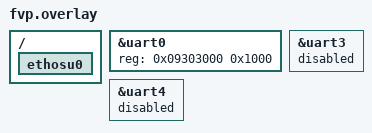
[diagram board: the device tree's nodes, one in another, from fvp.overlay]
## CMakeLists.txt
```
# SPDX-License-Identifier: Apache-2.0

cmake_minimum_required(VERSION 3.20.0)

# The AI layer adds its Kconfig fragments before Zephyr processes configuration.
add_subdirectory(ai_layer)

# Include the NPU node even when an older build cache has an empty overlay list.
if(NOT DTC_OVERLAY_FILE)
  set(DTC_OVERLAY_FILE "${CMAKE_CURRENT_SOURCE_DIR}/app.overlay")
endif()

find_package(Zephyr REQUIRED HINTS $ENV{ZEPHYR_BASE})
project(my_app)

# Zephyr already provides sys/types.h for AC6; the bare-metal pack shim
# must not shadow it. Only libc++ needs compatibility adjustments here.
if(CMAKE_CXX_COMPILER_ID STREQUAL "ARMClang")
  # AC6 6.24's register coalescer crashes on this pack's quantization code
  # with hard-float at both -Og and -O1. Keep the workaround on that file.
  if(CMAKE_CXX_COMPILER_VERSION VERSION_EQUAL "6.24.0" AND CONFIG_FP_HARDABI)
    get_target_property(_et_sources cmsis_executorch SOURCES)
    foreach(_source IN LISTS _et_sources)
      if(_source MATCHES "[/\\\\]op_quantize\\.cpp$")
        set_property(SOURCE "${_source}" TARGET_DIRECTORY cmsis_executorch
          APPEND PROPERTY COMPILE_OPTIONS -O0)
      endif()
    endforeach()
  endif()

  # Zephyr explicitly adds AC6's C resource headers as system includes.
  # AC6 6.24's libc++ wrappers must precede them (notably stddef.h).
  get_filename_component(_ac6_bin "${CMAKE_CXX_COMPILER}" DIRECTORY)
  get_filename_component(_ac6_libcxx "${_ac6_bin}/../include/libcxx" ABSOLUTE)
  if(IS_DIRECTORY "${_ac6_libcxx}")
    target_include_directories(zephyr_interface SYSTEM BEFORE INTERFACE
      "$<$<COMPILE_LANGUAGE:CXX>:${_ac6_libcxx}>")
  endif()
  zephyr_compile_options(
    "$<$<COMPILE_LANGUAGE:CXX>:-include${CMAKE_CURRENT_SOURCE_DIR}/src/zephyr_ac6_compat.hpp>")

  # Zephyr's CMake scatter generator disables CONFIG_STATIC_INIT_GNU,
  # omitting the constructor runner and the companion destructor handler.
  if(NOT CONFIG_STATIC_INIT_GNU)
    zephyr_linker_section_configure(SECTION ctors
      INPUT ".init_array*" SORT NAME KEEP
      SYMBOLS __ac6_init_array_start __ac6_init_array_end)
    zephyr_link_libraries("--keep=*.o(.init_array*)")
    target_sources(app PRIVATE src/zephyr_ac6_init.c
      "${ZEPHYR_BASE}/lib/cpp/abi/cpp_dtors.c")
  endif()

  # Zephyr hard-codes microlib for armlink. ExecuTorch's full libc++ needs
  # the standard Arm C runtime (wide strings and AEABI assertions).
  foreach(_elf zephyr_pre0 zephyr_pre1 zephyr_final)
    if(TARGET ${_elf})
      get_target_property(_libs ${_elf} LINK_LIBRARIES)
      list(REMOVE_ITEM _libs "--library_type=microlib")
      set_property(TARGET ${_elf} PROPERTY LINK_LIBRARIES "${_libs}")
    endif()
  endforeach()
endif()

target_sources(app PRIVATE
  src/main.c
  src/arm_embedded_module.cpp
  src/executorch_test.cpp
)

# Keep runtime logging consistent with the existing AI layer configuration.
zephyr_compile_definitions(ET_LOG_ENABLED=0)
```

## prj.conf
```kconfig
# M55_HP boot address used by the board's existing Alif boot configuration.
CONFIG_USE_DT_CODE_PARTITION=n
CONFIG_FLASH_LOAD_OFFSET=0x200000

# E8 NPU-HG: Ethos-U85 with 256 MACs per cycle.
CONFIG_ETHOS_U=y
CONFIG_ETHOS_U85_256=y
CONFIG_ETHOS_U_ARM=y
#CONFIG_ETHOS_U_LOG_LEVEL_NONE=y

# Ethos-U synchronization uses the kernel heap.
CONFIG_HEAP_MEM_POOL_SIZE=16384
# C++ allocations must use a heap initialized by Zephyr, including with AC6.
CONFIG_COMMON_LIBC_MALLOC=y
CONFIG_COMMON_LIBC_MALLOC_ARENA_SIZE=65536
CONFIG_LOG=y
# Keep the boot banner and kernel logs in order with the runtime's direct printf.
CONFIG_LOG_MODE_IMMEDIATE=y
CONFIG_ETHOS_U_LOG_LEVEL_INF=y
CONFIG_CACHE_MANAGEMENT=y
CONFIG_ETHOS_U_DCACHE=y

CONFIG_CPP=y
CONFIG_STD_CPP17=y

# Use the Cortex-M hardware FPU and pass floating-point arguments in FP registers.
CONFIG_FPU=y
CONFIG_FP_HARDABI=y

# Runtime loading uses C++ containers; the runner also prints float logits.
CONFIG_MAIN_STACK_SIZE=16384
CONFIG_REQUIRES_FLOAT_PRINTF=y
```

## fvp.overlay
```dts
/* SPDX-License-Identifier: Apache-2.0 */

/*
 * The Corstone-320 Zephyr board already declares its Ethos-U85. Keep this
 * overlay separate from app.overlay, which contains the Alif E8 NPU node.
 */

/* The installed SSE-320 FVP uses the BSP's FPGA UART window at 0x59303000.
 * reg is relative to the peripheral bus's 0x50000000 base.
 */
&uart0 {
	reg = <0x09303000 0x1000>;
};

/* These external UARTs use GPIO pin muxing that faults on the FVP.
 * Keep the UART0 console; the application does not use UART3 or UART4.
 */
&uart3 {
	status = "disabled";
};

&uart4 {
	status = "disabled";
};

/ {
	ethosu0 {
		status = "okay";
	};
};
```

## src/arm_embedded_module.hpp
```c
/*
 * Copyright (c) Meta Platforms, Inc. and affiliates.
 * All rights reserved.
 *
 * This source code is licensed under the BSD-style license found in
 * src/LICENSE-ExecuTorch (the ExecuTorch license).
 *
 * Customization for embedded systems by Arm.
 */
#pragma once

#include <executorch/runtime/executor/program.h>
#include <executorch/runtime/core/data_loader.h>

#include <memory>
#include <string>
#include <unordered_map>
#include <unordered_set>
#include <vector>

using namespace ::executorch::runtime;

namespace arm
{
  namespace embedded
  {

    /**
     * A facade class for loading programs and executing methods within them.
     */
    class EmbeddedModule
    {
    public:
      /**
       * Constructs an instance with the provided PTE data and memory allocators.
       *
       * @param[in] pte_data Pointer to the ExecuTorch program data to load.
       * @param[in] pte_size Size of the ExecuTorch program data to load.
       * @param[in] memory_allocator A MemoryAllocator used for memory planning.
       * @param[in] temp_allocator A MemoryAllocator to use when allocating
       * temporary data during kernel or delegate execution.
       */
      explicit EmbeddedModule(
          const unsigned char *pte_data,
          size_t pte_size,
          std::unique_ptr<DataLoader> data_loader = nullptr,
          std::unique_ptr<MemoryAllocator> memory_allocator = nullptr,
          std::unique_ptr<MemoryAllocator> temp_allocator = nullptr);

      /**
       * Loads the program if needed.
       *
       * @param[in] verification The type of verification to do before returning
       * success.
       *
       * @returns An Error to indicate success or failure of the loading process.
       */
      ET_NODISCARD Error load(
          const Program::Verification verification =
              Program::Verification::Minimal);

      /**
       * Checks if the program is loaded.
       *
       * @returns true if the program is loaded, false otherwise.
       */
      inline bool is_loaded() const
      {
        return program_ != nullptr;
      }

      /**
       * Get the program. The data loader used by the program is guaranteed to be
       * valid for the lifetime of the program.
       *
       * @returns Shared pointer to the program or nullptr if it's not yet loaded.
       */
      inline std::shared_ptr<Program> program() const
      {
        return program_;
      }

      /**
       * Get the number of methods available in the loaded program.
       *
       * @returns A Result object containing either the number of methods available
       *          or an error to indicate failure.
       */
      Result<size_t> num_methods();

      /**
       * Get a list of method names available in the loaded program.
       * Loads the program and method if needed.
       *
       * @returns A set of strings containing the names of the methods, or an error
       * if the program or method failed to load.
       */
      Result<std::unordered_set<std::string>> method_names();

      /**
       * Load a specific method from the program and set up memory management if
       * needed. The loaded method is cached to reuse the next time it's executed.
       *
       * @param[in] method_name The name of the method to load.
       * @param[in] planned_memory The memory-planned buffers to use for mutable
       * tensor data when executing a method.
       * @param[in] event_tracer Per-method event tracer to profile/trace methods
       * individually. When not given, the event tracer passed to the
       * EmbeddedModule constructor is used. Otherwise, this per-method event tracer
       * takes precedence.
       *
       * @returns An Error to indicate success or failure.
       */
      ET_NODISCARD
      Error load_method(
          const std::string &method_name,
          HierarchicalAllocator *planned_memory = nullptr,
          EventTracer *event_tracer = nullptr);

      #if 0
      ET_DEPRECATED ET_NODISCARD Error inline load_method(
          const std::string &method_name,
          EventTracer *event_tracer)
      {
        return load_method(method_name, nullptr, event_tracer);
      }
      #endif

      /**
       * Unload a specific method from the program.
       *
       * @param[in] method_name The name of the method to unload.
       *
       * @returns True if the method is unloaded, false if no-op.
       */
      inline bool unload_method(const std::string &method_name)
      {
        return methods_.erase(method_name);
      }

      #if 0
      /**
       * DEPRECATED: EmbeddedModule manages each Method exclusively.
       *
       * Get a method by it's name. Not recommended to use this method directly as
       * an end user. It's exposed to allow for composability of module in apis that
       * operate on method.
       *
       * @param[in] method_name The name of the method to get.
       *
       * @returns A Result object containing either a pointer to the requested
       *          method or an error to indicate failure.
       */
      ET_DEPRECATED ET_NODISCARD Result<Method *> method(
          const std::string &method_name);
      #endif

      /**
       * Checks if a specific method is loaded.
       *
       * @param[in] method_name The name of the method to check.
       *
       * @returns true if the method specified by method_name is loaded, false
       * otherwise.
       */
      inline bool is_method_loaded(const std::string &method_name) const
      {
        return methods_.count(method_name);
      }

      /**
       * Get a method metadata struct by method name.
       * Loads the program if needed.
       *
       * @param[in] method_name The name of the method to get the metadata for.
       *
       * @returns A method metadata, or an error if the program or method failed to
       * load.
       */
      Result<MethodMeta> method_meta(const std::string &method_name);

      /**
       * Execute a specific method with the given input values and retrieve the
       * output values. Loads the program and method before executing if needed.
       *
       * @param[in] method_name The name of the method to execute.
       * @param[in] input_values A vector of input values to be passed to the
       * method.
       *
       * @returns A Result object containing either a vector of output values
       *          from the method or an error to indicate failure.
       */
      ET_NODISCARD Result<std::vector<EValue>> execute(
          const std::string &method_name,
          const std::vector<EValue> &input_values);

      /**
       * Execute a specific method with a single input value.
       * Loads the program and method before executing if needed.
       *
       * @param[in] method_name The name of the method to execute.
       * @param[in] input_value A value to be passed to the method.
       *
       * @returns A Result object containing either a vector of output values
       *          from the method or an error to indicate failure.
       */
      ET_NODISCARD inline Result<std::vector<EValue>> execute(
          const std::string &method_name,
          const EValue &input_value)
      {
        return execute(method_name, std::vector<EValue>{input_value});
      }

      /**
       * Execute a specific method without any input values.
       * Loads the program and method before executing if needed.
       *
       * @param[in] method_name The name of the method to execute.
       *
       * @returns A Result object containing either a vector of output values
       *          from the method or an error to indicate failure.
       */
      ET_NODISCARD inline Result<std::vector<EValue>> execute(
          const std::string &method_name)
      {
        return execute(method_name, std::vector<EValue>{});
      }

      /**
       * Retrieve the output value of a specific method with the given input values.
       * Loads the program and method before execution if needed.
       *
       * @param[in] method_name The name of the method to execute.
       * @param[in] input_values A vector of input values to be passed to the
       * method.
       *
       * @returns A Result object containing either the first output value from the
       * method or an error to indicate failure.
       */
      ET_NODISCARD inline Result<EValue> get(
          const std::string &method_name,
          const std::vector<EValue> &input_values)
      {
        auto execute_result = execute(method_name, input_values);
        if (!execute_result.ok())
        {
          return execute_result.error();
        }
        auto result = std::move(*execute_result);
        if (result.empty())
        {
          return Error::InvalidArgument;
        }
        return result[0];
      }

      /**
       * Retrieve the output value of a specific method with a single input value.
       * Loads the program and method before execution if needed.
       *
       * @param[in] method_name The name of the method to execute.
       * @param[in] input_value A value to be passed to the method.
       *
       * @returns A Result object containing either the first output value from the
       * method or an error to indicate failure.
       */
      ET_NODISCARD inline Result<EValue> get(
          const std::string &method_name,
          const EValue &input_value)
      {
        return get(method_name, std::vector<EValue>{input_value});
      }

      /**
       * Retrieve the output value of a specific method without any input values.
       * Loads the program and method before execution if needed.
       *
       * @param[in] method_name The name of the method to execute.
       *
       * @returns A Result object containing either the first output value from the
       * method or an error to indicate failure.
       */
      ET_NODISCARD inline Result<EValue> get(
          const std::string &method_name)
      {
        return get(method_name, std::vector<EValue>{});
      }

      /**
       * Execute the 'forward' method with the given input values and retrieve the
       * output values. Loads the program and method before executing if needed.
       *
       * @param[in] input_values A vector of input values for the 'forward' method.
       *
       * @returns A Result object containing either a vector of output values
       *          from the 'forward' method or an error to indicate failure.
       */
      ET_NODISCARD inline Result<std::vector<EValue>> forward(
          const std::vector<EValue> &input_values)
      {
        return execute("forward", input_values);
      };

      /**
       * Execute the 'forward' method with a single value.
       * Loads the program and method before executing if needed.
       *
       * @param[in] input_value A value for the 'forward' method.
       *
       * @returns A Result object containing either a vector of output values
       *          from the 'forward' method or an error to indicate failure.
       */
      ET_NODISCARD inline Result<std::vector<EValue>> forward(
          const EValue &input_value)
      {
        return forward(std::vector<EValue>{input_value});
      }

      /**
       * Execute the 'forward' method without any input values.
       * Loads the program and method before executing if needed.
       *
       * @returns A Result object containing either a vector of output values
       *          from the method or an error to indicate failure.
       */
      ET_NODISCARD inline Result<std::vector<EValue>> forward()
      {
        return forward(std::vector<EValue>{});
      }

      /**
       * Sets a single input value for a specific method.
       *
       * @param[in] method_name The name of the method.
       * @param[in] input_value The EValue to set as the method input.
       * @param[in] input_index Zero-based index of the input to set.
       *
       * @returns An Error to indicate success or failure.
       */
      ET_NODISCARD
      Error set_input(
          const std::string &method_name,
          const EValue &input_value,
          size_t input_index);

      /**
       * Sets a single input value for the "forward" method.
       *
       * @param[in] input_value The EValue to set as the method input.
       * @param[in] input_index Zero-based index of the input to set.
       *
       * @returns An Error to indicate success or failure.
       */
      ET_NODISCARD
      inline Error set_input(
          const EValue &input_value,
          size_t input_index)
      {
        return set_input("forward", input_value, input_index);
      }

      /**
       * Sets all input values for a specific method.
       *
       * @param[in] method_name The name of the method.
       * @param[in] input_values A vector of EValues to set as the method inputs.
       *
       * @returns An Error to indicate success or failure.
       */
      ET_NODISCARD
      Error set_inputs(
          const std::string &method_name,
          const std::vector<EValue> &input_values);

      /**
       * Sets all input values for the "forward" method.
       *
       * @param[in] input_values A vector of EValues to set as the method inputs.
       *
       * @returns An Error to indicate success or failure.
       */
      ET_NODISCARD
      inline Error set_inputs(
          const std::vector<EValue> &input_values)
      {
        return set_inputs("forward", input_values);
      }

      /**
       * Sets the output tensor for a specific method.
       *
       * @param[in] method_name The name of the method.
       * @param[in] output_value The EValue containing the Tensor to set as the
       * method output.
       * @param[in] output_index Zero-based index of the output to set.
       *
       * @returns An Error to indicate success or failure.
       *
       * @note Only Tensor outputs are currently supported for setting.
       */
      ET_NODISCARD
      Error set_output(
          const std::string &method_name,
          EValue output_value,
          size_t output_index = 0);

      /**
       * Sets the output tensor for the "forward" method.
       *
       * @param[in] output_value The EValue containing the Tensor to set as the
       * method output.
       * @param[in] output_index Zero-based index of the output to set.
       *
       * @returns An Error to indicate success or failure.
       *
       * @note Only Tensor outputs are currently supported for setting.
       */
      ET_NODISCARD
      inline Error set_output(
          EValue output_value,
          size_t output_index = 0)
      {
        return set_output("forward", std::move(output_value), output_index);
      }

      /**
       * Sets all output tensors for a specific method.
       *
       * Loads the program and method if needed, and for each output uses
       * the provided tensor's data buffer as the method's output buffer.
       *
       * @param[in] method_name The name of the method.
       * @param[in] output_values A vector of EValues to set as the method outputs.
       *
       * @returns An Error to indicate success or failure.
       *
       * @note Only Tensor outputs are currently supported for setting.
       * @note Will fail for outputs that are memory-planned or constants.
       */
      ET_NODISCARD
      Error set_outputs(
          const std::string &method_name,
          const std::vector<EValue> &output_values);

      /**
       * Sets all output tensors for the "forward" method.
       *
       * @param[in] output_values A vector of EValues to set as the method outputs.
       *
       * @returns An Error to indicate success or failure.
       *
       * @note Only Tensor outputs are currently supported for setting.
       * @note Will fail for outputs that are memory-planned or constants.
       */
      ET_NODISCARD
      inline Error set_outputs(
          const std::vector<EValue> &output_values)
      {
        return set_outputs("forward", output_values);
      }

      /**
       * Retrieve all current output values of a specific method without executing
       * it. Loads the program and method before retrieval if needed.
       *
       * @param[in] method_name The name of the method.
       *
       * @returns A Result containing the vector of output values, or an error.
       */
      ET_NODISCARD
      Result<std::vector<EValue>> get_outputs(
          const std::string &method_name);

      /**
       * Retrieve all current output values of the "forward" method without
       * executing it. Loads the program and method before retrieval if needed.
       *
       * @returns A Result containing the vector of output values, or an error.
       */
      ET_NODISCARD
      inline Result<std::vector<EValue>> get_outputs()
      {
        return get_outputs("forward");
      }

      /**
       * Retrieve a single current output value of a specific method without
       * executing it. Loads the program and method before retrieval if needed.
       *
       * @param[in] method_name The name of the method.
       * @param[in] output_index Zero-based index of the output to retrieve.
       *
       * @returns A Result containing the requested output value, or an error.
       */
      ET_NODISCARD
      Result<EValue> get_output(
          const std::string &method_name,
          size_t output_index = 0);

      /**
       * Retrieve a single current output value of the "forward" method without
       * executing it. Loads the program and method before retrieval if needed.
       *
       * @param[in] output_index Zero-based index of the output to retrieve.
       *
       * @returns A Result containing the requested output value, or an error.
       */
      ET_NODISCARD
      inline Result<EValue> get_output(size_t output_index = 0)
      {
        return get_output("forward", output_index);
      }

      /**
       * Retrieves the EventTracer instance being used by the EmbeddedModule.
       * EventTracer is used for tracking and logging events during the execution
       * of methods.
       *
       * @returns A pointer to the EventTracer instance. Returns nullptr if no
       * EventTracer is set.
       */
      inline EventTracer *event_tracer() const
      {
        return event_tracer_.get();
      }

    private:
      struct MethodHolder
      {
        std::vector<uint8_t *> planned_buffers;
        std::vector<Span<uint8_t>> planned_spans;
        std::unique_ptr<HierarchicalAllocator> planned_memory;
        std::unique_ptr<MemoryManager> memory_manager;
        std::unique_ptr<Method> method;
      };

      std::shared_ptr<Program> program_;
      std::unique_ptr<DataLoader> data_loader_;
      std::unique_ptr<MemoryAllocator> memory_allocator_;
      std::unique_ptr<MemoryAllocator> temp_allocator_;
      // std::unique_ptr<NamedDataMap> merged_data_map_;

      std::unique_ptr<EventTracer> event_tracer_;

      [[maybe_unused]] const unsigned char *pte_data_;
      [[maybe_unused]] size_t pte_size_;

    protected:
      std::unordered_map<std::string, MethodHolder> methods_;
    };

  } // namespace embedded
} // namespace arm
```

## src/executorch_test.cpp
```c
// Copyright 2026 Arm Limited and/or its affiliates.
// SPDX-License-Identifier: Apache-2.0
// Adapted from CMSIS-Executorch/src/app_main.cpp for the Zephyr application.

#include <array>
#include <cstdint>
#include <cstdio>
#include <cstring>
#include <memory>

#include <zephyr/linker/devicetree_regions.h>

#include <executorch/extension/data_loader/buffer_data_loader.h>
#include <executorch/runtime/core/evalue.h>
#include <executorch/runtime/core/exec_aten/exec_aten.h>
#include <executorch/runtime/core/memory_allocator.h>
#include <executorch/runtime/platform/runtime.h>

#include "arm_embedded_module.hpp"
#include "executorch_test.h"
#include "model_pte.h"

using arm::embedded::EmbeddedModule;
using executorch::aten::DimOrderType;
using executorch::aten::ScalarType;
using executorch::aten::SizesType;
using executorch::aten::Tensor;
using executorch::aten::TensorImpl;
using executorch::extension::BufferDataLoader;
using executorch::runtime::EValue;
using executorch::runtime::MemoryAllocator;

namespace {

// TinyCNN needs much less space than the original example's two 4 MiB pools.
constexpr size_t kMethodPoolSize = 128 * 1024;
constexpr size_t kTempPoolSize = 64 * 1024;

alignas(64) uint8_t g_method_pool[kMethodPoolSize];
// The NPU uses scratch directly. Keep it in system SRAM rather than CPU-local DTCM.
alignas(64) uint8_t g_temp_pool[kTempPoolSize]
#if DT_NODE_EXISTS(DT_NODELABEL(sram0))
    Z_GENERIC_SECTION(LINKER_DT_NODE_REGION_NAME(DT_NODELABEL(sram0)))
#endif
    ; // On FVP the default RAM is already system SRAM.

} // namespace

extern "C" int executorch_run_test(void)
{
  executorch::runtime::runtime_init();
  printf("ExecuTorch Ethos-U85-256 application: %lu byte model\n", model_pte_size);

  // Devicetree memory-region sections are NOLOAD and are not zeroed at boot.
  std::memset(g_temp_pool, 0, sizeof(g_temp_pool));

  EmbeddedModule module(
      model_pte, model_pte_size,
      std::make_unique<BufferDataLoader>(model_pte, model_pte_size),
      std::make_unique<MemoryAllocator>(kMethodPoolSize, g_method_pool),
      std::make_unique<MemoryAllocator>(kTempPoolSize, g_temp_pool));

  // Same deterministic image values as the CMSIS pack example. The supplied
  // U85 PTE exposes NCHW, whereas the original runner hard-codes NHWC.
  alignas(16) static float input_data[16 * 16 * 3];
  auto method_meta = module.method_meta("forward");
  if (!method_meta.ok()) {
    printf("Could not read forward metadata (err=%u)\nTest_result: FAIL\n",
           static_cast<unsigned>(method_meta.error()));
    return 1;
  }
  if (method_meta->num_inputs() != 1) {
    printf("forward expected one input\nTest_result: FAIL\n");
    return 1;
  }
  auto input_meta = method_meta->input_tensor_meta(0);
  if (!input_meta.ok() || input_meta->scalar_type() != ScalarType::Float ||
      input_meta->sizes().size() != 4 || input_meta->dim_order().size() != 4 ||
      input_meta->nbytes() != sizeof(input_data)) {
    printf("forward expected a rank-four RGB image with 768 floats\n"
           "Test_result: FAIL\n");
    return 1;
  }

  for (size_t i = 0; i < sizeof(input_data) / sizeof(input_data[0]); ++i) {
    input_data[i] = static_cast<float>(i % 32) / 32.0f - 0.5f;
  }
  std::array<SizesType, 4> sizes;
  std::array<DimOrderType, 4> dim_order;
  for (size_t i = 0; i < sizes.size(); ++i) {
    sizes[i] = input_meta->sizes()[i];
    dim_order[i] = input_meta->dim_order()[i];
  }
  printf("Input shape: [%ld, %ld, %ld, %ld]\n", static_cast<long>(sizes[0]),
         static_cast<long>(sizes[1]), static_cast<long>(sizes[2]),
         static_cast<long>(sizes[3]));
  TensorImpl input_impl(ScalarType::Float, sizes.size(), sizes.data(), input_data,
                        dim_order.data());
  Tensor input(&input_impl);

  auto outputs = module.forward(input);
  if (!outputs.ok()) {
    printf("forward failed (err=%u)\nTest_result: FAIL\n",
           static_cast<unsigned>(outputs.error()));
    return 1;
  }
  if (outputs->size() != 1 || !outputs->front().isTensor()) {
    printf("forward expected one output tensor\nTest_result: FAIL\n");
    return 1;
  }

  const EValue& out = outputs->front();
  Tensor tensor = out.toTensor();
  const auto num_output_elements = tensor.numel();
  if (tensor.scalar_type() != ScalarType::Float || num_output_elements != 10) {
    printf("forward expected ten float logits\nTest_result: FAIL\n");
    return 1;
  }

  // The signed element count is positive after the ten-logit check above.
  const auto output_count = static_cast<size_t>(num_output_elements);
  printf("Output: %zu element(s):", output_count);
  const float* data = tensor.const_data_ptr<float>();
  for (size_t i = 0; i < output_count; ++i) {
    printf(" %.4f", static_cast<double>(data[i]));
  }
  printf("\nTest_result: PASS\n");
  fflush(stdout);
  return 0;
}
```
